# STM32H753xx register map
File version: 1.0
Registers are 32-bit, read-write, reset 0x0 unless marked. A register's access mark holds for its fields unless they carry their own. Offsets are from the block's base; [hi:lo] are bit positions; {n}, {i} and the like mark numbered series.

## HASH
Base 0x48021400
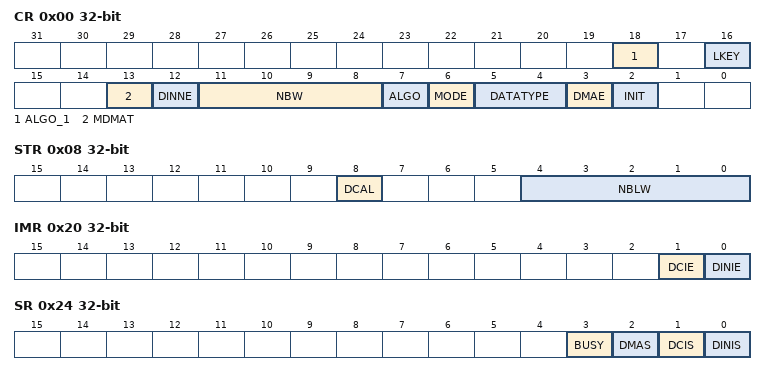
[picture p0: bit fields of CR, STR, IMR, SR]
0x00 CR — HASH control register
  [18] ALGO_1, [16] LKEY, [13] MDMAT, [12] DINNE, [11:8] NBW, [7] ALGO, [6] MODE, [5:4] DATATYPE, [3] DMAE, [2] INIT
0x04 DIN — HASH data input register
0x08 STR — HASH start register
  [8] DCAL, [4:0] NBLW
{0xC+4i} HR{i} (i=0..4) — HASH digest registers
0x20 IMR — HASH interrupt enable register
  [1] DCIE, [0] DINIE
0x24 SR — HASH status register
  [3] BUSY, [2] DMAS, [1] DCIS, [0] DINIS
{0xF8+4i} CSR{i} (i=0..53) — HASH context swap registers
{0x310+4i} DIGEST_HR{i} (i=0..7) — HASH digest registers

## RNG
Base 0x48021800
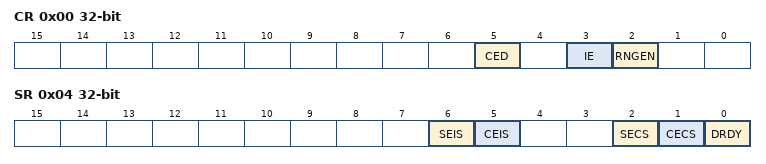
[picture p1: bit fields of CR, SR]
0x00 CR — RNG control register
  [5] CED, [3] IE, [2] RNGEN
0x04 SR — RNG status register
  [6] SEIS, [5] CEIS, [2] SECS, [1] CECS, [0] DRDY
0x08 DR — RNG data register

## DLYB_SDMMC2 — Delay Block DLYB
Base 0x48022800
Same registers: DLYB_QUADSPI 0x52006000, DLYB_SDMMC1 0x52008000
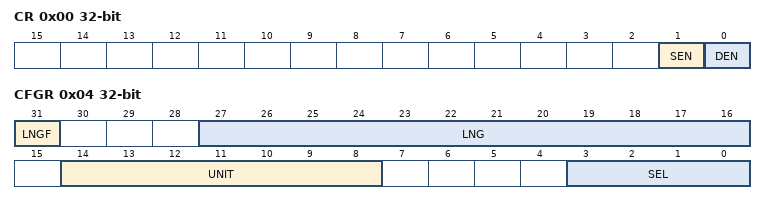
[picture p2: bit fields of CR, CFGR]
0x00 CR — DELAY BLOCK control register
  [1] SEN — Sampler length enable
  [0] DEN — Delay Block enable
0x04 CFGR — DELAY BLOCK configuration register
  [31] LNGF — Length valid flag
  [27:16] LNG — Delay line length value[11:0]
  [14:8] UNIT — Delay Defines the delay of a Unit delay cell[6:0]
  [3:0] SEL — Select the phase for the Output clock[3:0]

## RAMECC2
Base 0x48023000
Same registers: RAMECC1 0x52009000
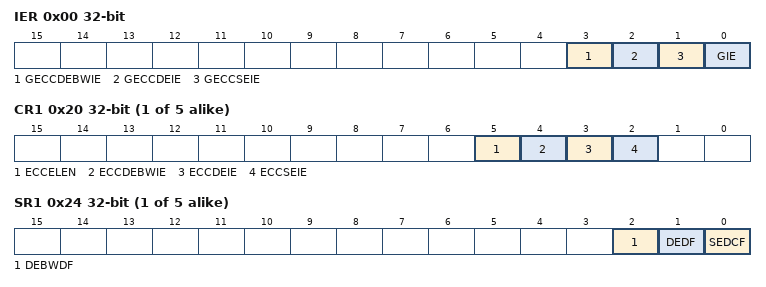
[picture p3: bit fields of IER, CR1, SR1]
0x00 IER — RAMECC interrupt enable register
  [3] GECCDEBWIE — Global ECC double error on byte write (BW) interrupt enable
  [2] GECCDEIE — Global ECC double error interrupt enable
  [1] GECCSEIE — Global ECC single error interrupt enable
  [0] GIE — Global interrupt enable
{0x0+0x20*i} CR{i} (i=1..5) — RAMECC monitor configuration register
  [5] ECCELEN — ECC error latching enable
  [4] ECCDEBWIE — ECC double error on byte write (BW) interrupt enable
  [3] ECCDEIE — ECC double error interrupt enable
  [2] ECCSEIE — ECC single error interrupt enable
{0x4+0x20*i} SR{i} (i=1..5) — RAMECC monitor status register
  [2] DEBWDF — ECC double error on byte write (BW) detected flag
  [1] DEDF — ECC double error detected flag
  [0] SEDCF — ECC single error detected and corrected flag
{0x8+0x20*i} FAR{i} (i=1..5) — RAMECC monitor failing address register
  [31:0] FADD — ECC error failing address
{0xC+0x20*i} FDRL{i} (i=1..5) — RAMECC monitor failing data low register
{0x10+0x20*i} FDRH{i} (i=1..5) — RAMECC monitor failing data high register
{0x14+0x20*i} FECR{i} (i=1..5) — RAMECC monitor failing ECC error code register
  [31:0] FEC — Failing error code

## RAMECC3
Base 0x58027000
Registers as RAMECC2, without CR{n} (n=3..5), SR{n} (n=3..5), FAR{n} (n=3..5), FDRL{n} (n=3..5), FDRH{n} (n=3..5), FECR{n} (n=3..5).

## WWDG1 — Window WATCHDOG
Base 0x50003000
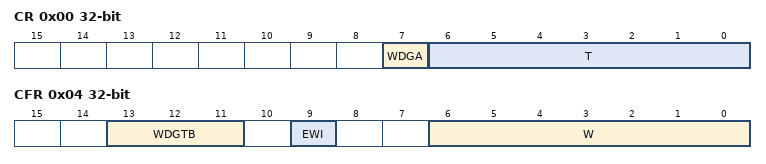
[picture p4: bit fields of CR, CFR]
0x00 CR — WWDG Control register
  [7] WDGA — Activation bit
  [6:0] T — T[6:0] bits (7-Bit counter (MSB to LSB))
0x04 CFR — WWDG Configuration register
  [13:11] WDGTB — WDGTB[2:0] bits (Timer Base)
    0=PRESCALER_1 (WWDG counter clock = (PCLK1/4096)/1); 1=PRESCALER_2 (WWDG counter clock = (PCLK1/4096)/2); 2=PRESCALER_4 (WWDG counter clock = (PCLK1/4096)/4); 3=PRESCALER_8 (WWDG counter clock = (PCLK1/4096)/8); 4=PRESCALER_16 (WWDG counter clock = (PCLK1/4096)/16); 5=PRESCALER_32 (WWDG counter clock = (PCLK1/4096)/32); 6=PRESCALER_64 (WWDG counter clock = (PCLK1/4096)/64); 7=PRESCALER_128 (WWDG counter clock = (PCLK1/4096)/128)
  [9] EWI — Early Wakeup Interrupt
  [6:0] W — W[6:0] bits (7-bit window value)
0x08 SR — WWDG Status register
  [0] EWIF — Early Wakeup Interrupt Flag

## GPV — Global Programmer View
Base 0x51000000
0x1FD0 AXI_PERIPH_ID_4 — AXI interconnect - peripheral ID4 register
{0x1FC0+4i} AXI_PERIPH_ID_{i} (i=5..7) — Reserved
{0x1FE0+4i} AXI_PERIPH_ID_{i} (i=0..3) — AXI interconnect - peripheral ID{i} register
{0x1FF0+4i} AXI_COMP_ID_{i} (i=0..3) — AXI interconnect - component ID{i} register
{0x1008+0x1000*i} AXI_TARG{i}_FN_MOD_ISS_BM (i=1..7) — AXI interconnect - TARG {i} bus matrix issuing functionality register
0x2024 AXI_TARG1_FN_MOD2 — AXI interconnect - TARG 1 bus matrix functionality 2 register
0x202C AXI_TARG1_FN_MOD_LB — AXI interconnect - TARG 1 long burst functionality modification register
0x2108 AXI_TARG1_FN_MOD — AXI interconnect - TARG 1 issuing functionality modification register
0x3024 AXI_TARG2_FN_MOD2 — AXI interconnect - TARG 2 bus matrix functionality 2 register
0x302C AXI_TARG2_FN_MOD_LB — AXI interconnect - TARG 2 long burst functionality modification register
0x3108 AXI_TARG2_FN_MOD — AXI interconnect - TARG 2 issuing functionality modification register
0x8024 AXI_TARG7_FN_MOD2 — AXI interconnect - TARG 7 bus matrix functionality 2 register
0x802C AXI_TARG7_FN_MOD_LB — AXI interconnect - TARG 7 long burst functionality modification register
0x8108 AXI_TARG7_FN_MOD — AXI interconnect - TARG 7 issuing functionality modification register
0x42024 AXI_INI1_FN_MOD2 — AXI interconnect - INI 1 functionality modification 2 register
0x42028 AXI_INI1_FN_MOD_AHB — AXI interconnect - INI 1 AHB functionality modification register
{0x41100+0x1000*i} AXI_INI{i}_READ_QOS (i=1..6) — AXI interconnect - INI {i} read QoS register
{0x41104+0x1000*i} AXI_INI{i}_WRITE_QOS (i=1..6) — AXI interconnect - INI {i} write QoS register
{0x41108+0x1000*i} AXI_INI{i}_FN_MOD (i=1..6) — AXI interconnect - INI {i} issuing functionality modification register
0x44024 AXI_INI3_FN_MOD2 — AXI interconnect - INI 3 functionality modification 2 register
0x44028 AXI_INI3_FN_MOD_AHB — AXI interconnect - INI 3 AHB functionality modification register
